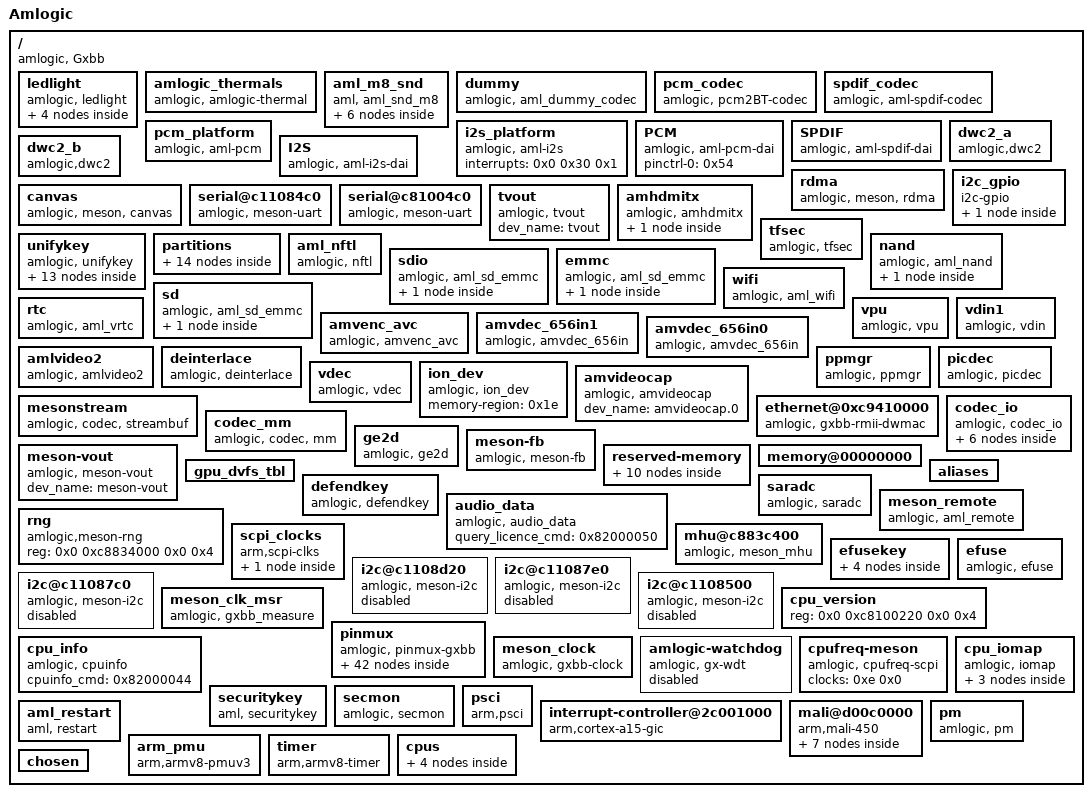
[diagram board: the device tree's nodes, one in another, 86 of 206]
/dts-v1/;

/ {
	#size-cells = <0x2>;
	#address-cells = <0x2>;
	interrupt-parent = <0x1>;
	amlogic-dt-id = "gxbb_p201_1g";
	compatible = "amlogic, Gxbb";
	model = "Amlogic";

	ledlight {
		ir_gpio_0 = <0x6a>;
		net_gpio_1 = <0x69>;
		net_gpio_0 = <0x68>;
		power_gpio_0 = <0x67>;
		status = "okay";
		dev_name = "ledlight";
		compatible = "amlogic, ledlight";

		gpio_b {
			phandle = <0x6a>;
			linux,phandle = <0x6a>;
			led_type = [42 00];
			led_active = <0x0>;
			led_gpio = <0x1a 0x58 0x0>;
			led_name = "ir_led";
		};

		gpio_g {
			phandle = <0x69>;
			linux,phandle = <0x69>;
			led_type = [47 00];
			led_active = <0x0>;
			led_gpio = <0x1a 0x52 0x0>;
			led_name = "net_led";
		};

		gpio_r {
			phandle = <0x68>;
			linux,phandle = <0x68>;
			led_type = [52 00];
			led_active = <0x0>;
			led_gpio = <0x1a 0x55 0x0>;
			led_name = "net_led";
		};

		gpio_rg {
			phandle = <0x67>;
			linux,phandle = <0x67>;
			led_type = "R&G";
			led_active = <0x1>;
			led_gpio = <0x6b 0xd 0x0>;
			led_name = "power_led";
		};
	};

	amlogic_thermals {
		keep_mode_min_range = <0x1f4 0x190 0x1 0x2>;
		keep_mode_max_range = <0x1ec300 0x29a 0x4 0x3>;
		keep_mode_threshold = <0x55>;
		keep_mode;
		idle_interval = <0x3e8>;
		cpu_cali_a = <0x0>;
		trip_point = <0x46 0x177001 0x177001 0x1ff 0x1ff 0x3 0x2 0x50 0x13c681 0x13c681 0x1b3 0x1b3 0x2 0x1 0x5a 0xfbf41 0xfbf41 0x148 0x148 0x2 0x1 0x104 0xffffffff 0xffffffff 0xffffffff 0xffffffff 0xffffffff 0xffffffff>;
		dev_name = "aml_thermal";
		#thermal-cells = <0x7>;
		compatible = "amlogic, amlogic-thermal";
	};

	aml_m8_snd {
		plat_list = <0x5f 0x5f 0x60>;
		codec_list = <0x5c 0x5d 0x5e>;
		cpu_list = <0x59 0x5a 0x5b>;
		pinctrl-1 = <0x58>;
		pinctrl-0 = <0x57>;
		pinctrl-names = "aml_snd_m8", "aml_snd_suspend";
		hp_paraments = <0x320 0x12c 0x0 0x5 0x1>;
		hp_disable;
		mute_gpio-gpios = <0x1a 0x13 0x0>;
		aml,audio-routing = "Ext Spk", "LOUTL", "Ext Spk", "LOUTR";
		aml_sound_card,name = "AML-M8AUDIO";
		aml-sound-card,format = "i2s";
		status = "okay";
		compatible = "aml, aml_snd_m8";

		codec2 {
			phandle = <0x5e>;
			linux,phandle = <0x5e>;
			sound-dai = <0x66>;
		};

		codec1 {
			phandle = <0x5d>;
			linux,phandle = <0x5d>;
			sound-dai = <0x65>;
		};

		codec0 {
			phandle = <0x5c>;
			linux,phandle = <0x5c>;
			sound-dai = <0x64>;
		};

		cpudai2 {
			phandle = <0x5b>;
			linux,phandle = <0x5b>;
			sound-dai = <0x63>;
		};

		cpudai1 {
			phandle = <0x5a>;
			linux,phandle = <0x5a>;
			sound-dai = <0x62>;
		};

		cpudai0 {
			phandle = <0x59>;
			linux,phandle = <0x59>;
			sound-dai = <0x61>;
		};
	};

	dummy {
		phandle = <0x64>;
		linux,phandle = <0x64>;
		status = "okay";
		compatible = "amlogic, aml_dummy_codec";
		#sound-dai-cells = <0x0>;
	};

	pcm_codec {
		phandle = <0x66>;
		linux,phandle = <0x66>;
		compatible = "amlogic, pcm2BT-codec";
		#sound-dai-cells = <0x0>;
	};

	spdif_codec {
		phandle = <0x65>;
		linux,phandle = <0x65>;
		pinctrl-1 = <0x56>;
		pinctrl-0 = <0x55>;
		pinctrl-names = "aml_audio_spdif", "aml_audio_spdif_suspend";
		compatible = "amlogic, aml-spdif-codec";
		#sound-dai-cells = <0x0>;
	};

	pcm_platform {
		phandle = <0x60>;
		linux,phandle = <0x60>;
		compatible = "amlogic, aml-pcm";
	};

	i2s_platform {
		phandle = <0x5f>;
		linux,phandle = <0x5f>;
		interrupts = <0x0 0x30 0x1>;
		compatible = "amlogic, aml-i2s";
	};

	PCM {
		phandle = <0x63>;
		linux,phandle = <0x63>;
		pinctrl-0 = <0x54>;
		pinctrl-names = "aml_audio_btpcm";
		compatible = "amlogic, aml-pcm-dai";
		#sound-dai-cells = <0x0>;
	};

	SPDIF {
		phandle = <0x62>;
		linux,phandle = <0x62>;
		clock-names = "mpll1", "i958", "mclk", "spdif", "clk_81";
		clocks = <0xb 0x20 0xb 0x24 0xb 0x22 0xb 0x25 0xb 0xa>;
		reset-names = "iec958", "iec958_amclk";
		resets = <0xb 0x27 0xb 0x90>;
		compatible = "amlogic, aml-spdif-dai";
		#sound-dai-cells = <0x0>;
	};

	I2S {
		phandle = <0x61>;
		linux,phandle = <0x61>;
		compatible = "amlogic, aml-i2s-dai";
		clock-names = "mpll0", "mclk";
		clocks = <0xb 0x1f 0xb 0x22>;
		reset-names = "top_glue", "aud_buf", "i2s_out", "amclk_measure", "aififo2", "aud_mixer", "mixer_reg", "adc", "top_level", "aoclk", "aud_in";
		resets = <0xb 0x26 0xb 0x12 0xb 0x28 0xb 0x29 0xb 0x2a 0xb 0x2b 0xb 0x2c 0xb 0x2d 0xb 0x2f 0xb 0x8e 0xb 0x22>;
		#sound-dai-cells = <0x0>;
	};

	dwc2_a {
		reset-names = "usb_general", "usb0", "usb0_to_ddr";
		resets = <0xb 0x3a 0xb 0x49 0xb 0x35>;
		cpu-type = "gxbaby";
		usb-fifo = <0x400>;
		phy-reg-size = <0x20>;
		phy-reg = <0xc0000000>;
		gpio-work-mask = <0x1>;
		gpios = <0x1a 0x45 0x0>;
		gpio-vbus-power = "GPIODV_24";
		port-id-mode = <0x1>;
		port-dma = <0x0>;
		port-config = <0x0>;
		port-speed = <0x0>;
		port-type = <0x1>;
		port-id = <0x0>;
		clock-src = "usb0";
		pl-periph-id = <0x0>;
		status = "okay";
		interrupts = <0x0 0x1e 0x4>;
		reg = <0x0 0xc9000000 0x0 0x40000>;
		compatible = "amlogic,dwc2";
	};

	dwc2_b {
		reset-names = "usb_general", "usb1", "usb1_to_ddr";
		resets = <0xb 0x3a 0xb 0x48 0xb 0x36>;
		cpu-type = "gxbaby";
		pmu-apply-power = <0x1>;
		host-only-core = <0x1>;
		usb-fifo = <0x400>;
		phy-reg-size = <0x20>;
		phy-reg = <0xc0000020>;
		port-id-mode = <0x1>;
		port-dma = <0x0>;
		port-config = <0x0>;
		port-speed = <0x0>;
		port-type = <0x1>;
		port-id = <0x1>;
		clock-src = "usb1";
		pl-periph-id = <0x1>;
		status = "okay";
		interrupts = <0x0 0x1f 0x4>;
		reg = <0x0 0xc9100000 0x0 0x40000>;
		compatible = "amlogic,dwc2";
	};

	rdma {
		interrupt-names = "rdma";
		interrupts = <0x0 0x59 0x1>;
		status = "ok";
		dev_name = "amlogic-rdma";
		compatible = "amlogic, meson, rdma";
	};

	canvas {
		reg = <0x0 0xc8838000 0x0 0x400>;
		status = "ok";
		dev_name = "amlogic-canvas";
		compatible = "amlogic, meson, canvas";
	};

	serial@c11084c0 {
		resets = <0xb 0xd>;
		pinctrl-0 = <0x53>;
		pinctrl-names = "default";
		fifosize = <0x80>;
		clock-names = "clk_uart";
		clocks = <0xb 0x2>;
		status = "okay";
		interrupts = <0x0 0x1a 0x1>;
		reg = <0x0 0xc11084c0 0x0 0x14>;
		compatible = "amlogic, meson-uart";
	};

	serial@c81004c0 {
		pinctrl-names = "default";
		fifosize = <0x40>;
		clock-names = "clk_uart";
		clocks = <0xb 0x2>;
		status = "okay";
		interrupts = <0x0 0xc1 0x1>;
		reg = <0x0 0xc81004c0 0x0 0x14>;
		compatible = "amlogic, meson-uart";
	};

	i2c_gpio {
		i2c-gpio,timeout-ms = <0xa>;
		#size-cells = <0x2>;
		#address-cells = <0x2>;
		gpios = <0x1a 0x11 0x0 0x1a 0x12 0x0>;
		i2c-gpio,delay-us = <0xa>;
		dev_name = "i2c-gpio";
		compatible = "i2c-gpio";

		i2c_gpio_edid {
			reg = <0x50 0x0 0x0 0x0>;
			compatible = "i2c-gpio-edid";
		};
	};

	tvout {
		status = "okay";
		dev_name = "tvout";
		compatible = "amlogic, tvout";
	};

	amhdmitx {
		ranges;
		#size-cells = <0x2>;
		#address-cells = <0x2>;
		gpio_i2c_en = <0x1>;
		clock-names = "hdmitx_clk_sys", "hdmitx_clk_encp", "hdmitx_clk_enci", "hdmitx_clk_pixel", "hdmitx_clk_phy", "hdmitx_clk_vid";
		clocks = <0xb 0xb 0xb 0xc 0xb 0xd 0xb 0xe 0xb 0xf 0xb 0x16>;
		interrupt-names = "hdmitx_hpd";
		interrupts = <0x0 0x39 0x1>;
		vend-data = <0x51>;
		pinctrl-1 = <0x50>;
		pinctrl-0 = <0x4f>;
		pinctrl-names = "hdmitx_hpd", "hdmitx_ddc";
		status = "okay";
		dev_name = "amhdmitx";
		compatible = "amlogic, amhdmitx";

		vend_data {
			phandle = <0x51>;
			linux,phandle = <0x51>;
			reg = <0x0 0xc810023c 0x0 0x4>;
			pinctrl-0 = <0x52>;
			pinctrl-names = "hdmitx_aocec";
			interrupt-names = "hdmitx_cec";
			interrupts = <0x0 0xc7 0x1>;
			cec_osd_string = "MBox";
			product_desc = "GXBB Mbox";
			vendor_id = <0x0>;
			vendor_name = "Amlogic";
			status = "okay";
			compatible = "amlogic, amlogic-cec";
		};
	};

	tfsec {
		tap_query_in = <0xb000ff0a>;
		tap_get_ci = <0xb000ff09>;
		tap_get_mac = <0xb000ff08>;
		tap_burn_mac = <0xb000ff07>;
		tap_burn_ci = <0xb000ff06>;
		tap_burn_sn = <0xb000ff05>;
		tap_burn_in = <0xb000ff04>;
		tap_decrypt_terminal_challenge = <0xb000ff03>;
		tap_decrypt_cloud_challenge = <0xb000ff02>;
		tap_get_sn = <0xb000ff01>;
		compatible = "amlogic, tfsec";
	};

	unifykey {
		unifykey-index-12 = <0x4e>;
		unifykey-index-11 = <0x4d>;
		unifykey-index-10 = <0x4c>;
		unifykey-index-9 = <0x4b>;
		unifykey-index-8 = <0x4a>;
		unifykey-index-7 = <0x49>;
		unifykey-index-6 = <0x48>;
		unifykey-index-5 = <0x47>;
		unifykey-index-4 = <0x46>;
		unifykey-index-3 = <0x45>;
		unifykey-index-2 = <0x44>;
		unifykey-index-1 = <0x43>;
		unifykey-index-0 = <0x42>;
		unifykey-num = <0xd>;
		status = "ok";
		compatible = "amlogic, unifykey";

		key_12 {
			phandle = <0x4e>;
			linux,phandle = <0x4e>;
			key-permit = "read", "write", "del";
			key-device = "normal";
			key-name = "stbid";
		};

		key_11 {
			phandle = <0x4d>;
			linux,phandle = <0x4d>;
			key-permit = "read", "write", "del";
			key-type = "raw";
			key-device = "secure";
			key-name = "telecomkeybox";
		};

		key_10 {
			phandle = <0x4c>;
			linux,phandle = <0x4c>;
			key-permit = "read", "write", "del";
			key-device = "secure";
			key-name = "hdcp22_fw_private";
		};

		key_9 {
			phandle = <0x4b>;
			linux,phandle = <0x4b>;
			key-permit = "read", "write", "del";
			key-device = "normal";
			key-name = "deviceid";
		};

		key_8 {
			phandle = <0x4a>;
			linux,phandle = <0x4a>;
			key-permit = "read", "write", "del";
			key-device = "secure";
			key-name = "widevinekeybox";
		};

		key_7 {
			phandle = <0x49>;
			linux,phandle = <0x49>;
			key-permit = "read", "write", "del";
			key-device = "normal";
			key-name = "hdcp2_rx";
		};

		key_6 {
			phandle = <0x48>;
			linux,phandle = <0x48>;
			key-permit = "read", "write", "del";
			key-device = "normal";
			key-name = "hdcp2_tx";
		};

		key_5 {
			phandle = <0x47>;
			linux,phandle = <0x47>;
			key-type = "mac";
			key-permit = "read", "write", "del";
			key-device = "normal";
			key-name = "mac_wifi";
		};

		key_4 {
			phandle = <0x46>;
			linux,phandle = <0x46>;
			key-type = "mac";
			key-permit = "read", "write", "del";
			key-device = "normal";
			key-name = "mac_bt";
		};

		key_3 {
			phandle = <0x45>;
			linux,phandle = <0x45>;
			key-permit = "write";
			key-device = "efuse";
			key-name = "secure_boot_set";
		};

		key_2 {
			phandle = <0x44>;
			linux,phandle = <0x44>;
			key-permit = "read", "write", "del";
			key-type = "sha1";
			key-device = "secure";
			key-name = "hdcp";
		};

		key_1 {
			phandle = <0x43>;
			linux,phandle = <0x43>;
			key-permit = "read", "write", "del";
			key-device = "normal";
			key-name = "mac";
		};

		key_0 {
			phandle = <0x42>;
			linux,phandle = <0x42>;
			key-permit = "read", "write", "del";
			key-device = "normal";
			key-name = "usid";
		};
	};

	partitions {
		part-13 = <0x41>;
		part-12 = <0x40>;
		part-11 = <0x3f>;
		part-10 = <0x3e>;
		part-9 = <0x3d>;
		part-8 = <0x3c>;
		part-7 = <0x3b>;
		part-6 = <0x3a>;
		part-5 = <0x39>;
		part-4 = <0x38>;
		part-3 = <0x37>;
		part-2 = <0x36>;
		part-1 = <0x35>;
		part-0 = <0x34>;
		parts = <0xe>;

		data {
			phandle = <0x41>;
			linux,phandle = <0x41>;
			mask = <0x4>;
			size = <0xffffffff 0xffffffff>;
			pname = "data";
		};

		params {
			phandle = <0x40>;
			linux,phandle = <0x40>;
			mask = <0x2>;
			size = <0x0 0x4000000>;
			pname = "params";
		};

		info {
			phandle = <0x3f>;
			linux,phandle = <0x3f>;
			mask = <0x4>;
			size = <0x0 0x4000000>;
			pname = "info";
		};

		ghost {
			phandle = <0x3e>;
			linux,phandle = <0x3e>;
			mask = <0x4>;
			size = <0x0 0x20000000>;
			pname = "ghost";
		};

		cache {
			phandle = <0x3d>;
			linux,phandle = <0x3d>;
			mask = <0x2>;
			size = <0x0 0x20000000>;
			pname = "cache";
		};

		system {
			phandle = <0x3c>;
			linux,phandle = <0x3c>;
			mask = <0x1>;
			size = <0x0 0x28000000>;
			pname = "system";
		};

		boot {
			phandle = <0x3b>;
			linux,phandle = <0x3b>;
			mask = <0x1>;
			size = <0x0 0x2000000>;
			pname = "boot";
		};

		instaboot {
			phandle = <0x3a>;
			linux,phandle = <0x3a>;
			mask = <0x1>;
			size = <0x0 0x20000000>;
			pname = "instaboot";
		};

		misc {
			phandle = <0x39>;
			linux,phandle = <0x39>;
			mask = <0x1>;
			size = <0x0 0x2000000>;
			pname = "misc";
		};

		crypt {
			phandle = <0x38>;
			linux,phandle = <0x38>;
			mask = <0x1>;
			size = <0x0 0x2000000>;
			pname = "crypt";
		};

		tee {
			phandle = <0x37>;
			linux,phandle = <0x37>;
			mask = <0x1>;
			size = <0x0 0x800000>;
			pname = "tee";
		};

		rsv {
			phandle = <0x36>;
			linux,phandle = <0x36>;
			mask = <0x1>;
			size = <0x0 0x800000>;
			pname = "rsv";
		};

		recovery {
			phandle = <0x35>;
			linux,phandle = <0x35>;
			mask = <0x1>;
			size = <0x0 0x2000000>;
			pname = "recovery";
		};

		logo {
			phandle = <0x34>;
			linux,phandle = <0x34>;
			mask = <0x1>;
			size = <0x0 0x2000000>;
			pname = "logo";
		};
	};

	aml_nftl {
		compatible = "amlogic, nftl";
	};

	nand {
		plat-part-0 = <0x33>;
		plat-num = <0x1>;
		plat-names = "nandnormal";
		device_id = <0x0>;
		pinctrl-2 = <0x32>;
		pinctrl-1 = <0x2f 0x30 0x31>;
		pinctrl-0 = <0x2f 0x30 0x31>;
		pinctrl-names = "nand_rb_mod", "nand_norb_mod", "nand_cs_pins_only";
		interrupts = <0x0 0x22 0x1>;
		reg = <0x0 0xd0074800 0x0 0x200>;
		status = "ok";
		dev_name = "nand";
		compatible = "amlogic, aml_nand";

		normal {
			phandle = <0x33>;
			linux,phandle = <0x33>;
			busy_pad = "rb0";
			enable_pad = "ce0", "ce1", "ce2", "ce3";
		};
	};

	sdio {
		pinctrl-1 = <0x2e>;
		pinctrl-0 = <0x2d>;
		pinctrl-names = "sdio_clk_cmd_pins", "sdio_all_pins";
		interrupts = <0x0 0xd8 0x4>;
		reg = <0x0 0xd0070000 0x0 0x2000>;
		status = "okay";
		dev_name = "aml_newsd.0";
		compatible = "amlogic, aml_sd_emmc";

		sdio {
			card_type = <0x3>;
			max_req_size = <0x20000>;
			f_max = <0xbebc200>;
			f_min = <0x61a80>;
			caps = "MMC_CAP_4_BIT_DATA", "MMC_CAP_MMC_HIGHSPEED", "MMC_CAP_SD_HIGHSPEED", "MMC_CAP_NONREMOVABLE", "MMC_CAP_UHS_SDR12", "MMC_CAP_UHS_SDR25", "MMC_CAP_UHS_SDR50", "MMC_CAP_UHS_SDR104", "MMC_PM_KEEP_POWER", "MMC_CAP_SDIO_IRQ";
			ocr_avail = <0x200080>;
			pinname = "sdio";
			status = "okay";
		};
	};

	emmc {
		pinctrl-1 = <0x2c>;
		pinctrl-0 = <0x2b>;
		pinctrl-names = "emmc_clk_cmd_pins", "emmc_all_pins";
		interrupts = <0x0 0xda 0x1>;
		reg = <0x0 0xd0074000 0x0 0x2000>;
		status = "okay";
		dev_name = "aml_newsd.0";
		compatible = "amlogic, aml_sd_emmc";

		emmc {
			card_type = <0x1>;
			hw_reset = <0x1a 0x1d 0x0>;
			gpio_dat3 = <0x1a 0x17 0x0>;
			max_req_size = <0x20000>;
			f_max = <0xbebc200>;
			f_min = <0x493e0>;
			caps2 = "MMC_CAP2_HS200";
			caps = "MMC_CAP_8_BIT_DATA", "MMC_CAP_MMC_HIGHSPEED", "MMC_CAP_SD_HIGHSPEED", "MMC_CAP_NONREMOVABLE", "MMC_CAP_1_8V_DDR", "MMC_CAP_HW_RESET", "MMC_CAP_ERASE", "MMC_CAP_CMD23";
			ocr_avail = <0x200080>;
			pinname = "emmc";
			status = "okay";
		};
	};

	sd {
		pinctrl-8 = <0x2a>;
		pinctrl-7 = <0x29>;
		pinctrl-6 = <0x28>;
		pinctrl-5 = <0x27>;
		pinctrl-4 = <0x26>;
		pinctrl-3 = <0x25>;
		pinctrl-2 = <0x24>;
		pinctrl-1 = <0x23>;
		pinctrl-0 = <0x22>;
		pinctrl-names = "sd_clk_cmd_pins", "sd_all_pins", "sd_1bit_pins", "sd_clk_cmd_uart_pins", "sd_1bit_uart_pins", "sd_to_ao_uart_pins", "ao_to_sd_uart_pins", "ao_to_sd_jtag_pins", "sd_to_ao_jtag_pins";
		interrupts = <0x0 0xd9 0x1 0x0 0x43 0x1 0x0 0x45 0x1>;
		reg = <0x0 0xd0072000 0x0 0x2000>;
		status = "okay";
		dev_name = "aml_newsd.0";
		compatible = "amlogic, aml_sd_emmc";

		sd {
			card_type = <0x5>;
			irq_out = <0x5>;
			irq_in = <0x3>;
			gpio_cd = <0x1a 0x2c 0x0>;
			jtag_pin = <0x1a 0x26 0x0>;
			gpio_dat3 = <0x1a 0x2a 0x0>;
			max_req_size = <0x20000>;
			tx_phase = <0x0>;
			f_max = <0x5f5e100>;
			f_min = <0x61a80>;
			caps = "MMC_CAP_4_BIT_DATA", "MMC_CAP_MMC_HIGHSPEED", "MMC_CAP_SD_HIGHSPEED";
			ocr_avail = <0x200080>;
			pinname = "sd";
			port = <0x1>;
			status = "okay";
		};
	};

	wifi {
		pinctrl-0 = <0x21>;
		pinctrl-names = "wifi_32k_pins";
		dhd_static_buf;
		power_on_pin = <0x1a 0x62 0x0>;
		irq_trigger_type = "GPIO_IRQ_HIGH";
		interrupts = <0x0 0x44 0x4>;
		interrupt_pin = <0x1a 0x63 0x0>;
		status = "okay";
		dev_name = "aml_wifi";
		compatible = "amlogic, aml_wifi";
	};

	rtc {
		status = "okay";
		init_date = "2015/01/01";
		timer_e_addr = <0xc1109988>;
		alarm_reg_addr = <0xc81000a8>;
		compatible = "amlogic, aml_vrtc";
	};

	vpu {
		clk_level = <0x7>;
		status = "ok";
		dev_name = "vpu";
		compatible = "amlogic, vpu";
	};

	amvenc_avc {
		interrupt-names = "mailbox_2";
		interrupts = <0x0 0x2d 0x1>;
		status = "okay";
		dev_name = "amvenc_avc";
		compatible = "amlogic, amvenc_avc";
	};

	amvdec_656in1 {
		bt656_id = <0x1>;
		clock-names = "fclk_div2", "cts_bt656_clk1";
		clocks = <0xb 0x7 0xb 0x27>;
		reg = <0x0 0xd0050000 0x0 0x7c>;
		status = "ok";
		dev_name = "amvdec_656in1";
		compatible = "amlogic, amvdec_656in";
	};

	amvdec_656in0 {
		bt656_id = <0x0>;
		clock-names = "fclk_div2", "cts_bt656_clk0";
		clocks = <0xb 0x7 0xb 0x26>;
		reg = <0x0 0xd0048000 0x0 0x7c>;
		status = "ok";
		dev_name = "amvdec_656in0";
		compatible = "amlogic, amvdec_656in";
	};

	vdin1 {
		vdin_id = <0x1>;
		clock-names = "xtal", "cts_vid_lock_clk";
		clocks = <0xb 0x2 0xb 0x28>;
		rdma-irq = <0x4>;
		interrupts = <0x0 0x55 0x1>;
		reserve-iomap = "true";
		status = "ok";
		dev_name = "vdin1";
		memory-region = <0x6>;
		compatible = "amlogic, vdin";
	};

	amlvideo2 {
		status = "okay";
		dev_name = "amlvideo2";
		memory-region = <0x20>;
		compatible = "amlogic, amlvideo2";
	};

	deinterlace {
		hw-version = <0x2>;
		buffer-size = <0x2fd000>;
		interrupt-names = "de_irq", "timerc";
		interrupts = <0x0 0x2e 0x1 0x0 0x6 0x1>;
		memory-region = <0x1f>;
		status = "okay";
		compatible = "amlogic, deinterlace";
	};

	ppmgr {
		status = "okay";
		dev_name = "ppmgr";
		memory-region = <0x1e>;
		compatible = "amlogic, ppmgr";
	};

	picdec {
		status = "okay";
		dev_name = "picdec";
		memory-region = <0x4>;
		compatible = "amlogic, picdec";
	};

	vdec {
		interrupt-names = "vsync", "demux", "parser", "mailbox_0", "mailbox_1", "mailbox_2";
		interrupts = <0x0 0x3 0x1 0x0 0x17 0x1 0x0 0x20 0x1 0x0 0x2b 0x1 0x0 0x2c 0x1 0x0 0x2d 0x1>;
		status = "okay";
		dev_name = "vdec.0";
		compatible = "amlogic, vdec";
	};

	ion_dev {
		memory-region = <0x1e>;
		compatible = "amlogic, ion_dev";
	};

	amvideocap {
		status = "okay";
		dev_name = "amvideocap.0";
		compatible = "amlogic, amvideocap";
	};

	mesonstream {
		reset-names = "parser_top", "vpu_intr", "demux", "vdec";
		resets = <0xb 0x39 0xb 0x59 0xb 0x24 0xb 0x1>;
		status = "okay";
		dev_name = "mesonstream";
		compatible = "amlogic, codec, streambuf";
	};

	ethernet@0xc9410000 {
		clock-names = "ethclk81";
		clocks = <0xb 0xa>;
		interrupt-names = "macirq";
		reset-names = "ethpower";
		resets = <0xb 0x23>;
		mc_val = <0x1800>;
		rst_pin-gpios = <0x1a 0xe 0x0>;
		pinctrl-0 = <0x1d>;
		pinctrl-names = "eth_pins";
		phy-mode = "rmii";
		interrupts = <0x0 0x8 0x1>;
		reg = <0x0 0xc9410000 0x0 0x10000 0x0 0xc8834540 0x0 0x8>;
		compatible = "amlogic, gxbb-rmii-dwmac";
	};

	codec_mm {
		status = "okay";
		dev_name = "codec_mm";
		memory-region = <0x3 0x1c>;
		compatible = "amlogic, codec, mm";
	};

	codec_io {
		ranges;
		#size-cells = <0x2>;
		#address-cells = <0x2>;
		compatible = "amlogic, codec_io";

		io_dmc_base {
			reg = <0x0 0xc8838000 0x0 0x400>;
		};

		io_vcbus_base {
			reg = <0x0 0xd0100000 0x0 0x40000>;
		};

		io_aobus_base {
			reg = <0x0 0xc8100000 0x0 0x100000>;
		};

		io_hiubus_base {
			reg = <0x0 0xc883c000 0x0 0x2000>;
		};

		io_dos_base {
			reg = <0x0 0xc8820000 0x0 0x10000>;
		};

		io_cbus_base {
			reg = <0x0 0xc1100000 0x0 0x100000>;
		};
	};

	ge2d {
		reset-names = "ge2d";
		resets = <0xb 0x34>;
		clock-names = "clk_vapb_0", "clk_ge2d";
		clocks = <0xb 0x17 0xb 0x19>;
		interrupt-names = "ge2d";
		interrupts = <0x0 0x96 0x1>;
		status = "okay";
		dev_name = "ge2d";
		compatible = "amlogic, ge2d";
	};

	meson-fb {
		display_size_default = <0x780 0x438 0x780 0xca8 0x20>;
		scale_mode = <0x1>;
		display_mode_default = "1080p60hz";
		mem_size = <0x1800000 0x100000>;
		interrupt-names = "viu-vsync", "rdma";
		interrupts = <0x0 0x3 0x1 0x0 0x59 0x1>;
		status = "okay";
		dev_name = "meson-fb";
		memory-region = <0x1b>;
		compatible = "amlogic, meson-fb";
	};

	meson-vout {
		status = "okay";
		dev_name = "meson-vout";
		compatible = "amlogic, meson-vout";
	};

	reserved-memory {
		ranges;
		#size-cells = <0x2>;
		#address-cells = <0x2>;

		linux,codec_mm_reserved {
			phandle = <0x1c>;
			linux,phandle = <0x1c>;
			alignment = <0x0 0x100000>;
			size = <0x0 0x4100000>;
			compatible = "amlogic, codec-mm-reserved";
		};

		linux,picdec {
			linux,contiguous-region;
			alignment = <0x0 0x0>;
			size = <0x0 0x0>;
			reusable;
			linux,phandle = <0x4>;
			compatible = "shared-dma-pool";
		};

		linux,codec_mm_cma {
			linux,contiguous-region;
			alignment = <0x0 0x400000>;
			size = <0x0 0xd000000>;
			reusable;
			linux,phandle = <0x3>;
			compatible = "shared-dma-pool";
		};

		linux,amlvideo2 {
			phandle = <0x20>;
			linux,phandle = <0x20>;
			size = <0x0 0x1800000>;
			compatible = "amlogic, amlvideo2_memory";
		};

		linux,vdin1_cma {
			alignment = <0x0 0x400000>;
			size = <0x0 0x1400000>;
			reusable;
			linux,phandle = <0x6>;
			compatible = "shared-dma-pool";
		};

		linux,ion-dev {
			phandle = <0x1e>;
			linux,phandle = <0x1e>;
			multi-use;
			size = <0x0 0x2000000>;
			compatible = "amlogic, idev-mem";
		};

		linux,di {
			phandle = <0x1f>;
			linux,phandle = <0x1f>;
			multi-use;
			size = <0x0 0x1e00000>;
			compatible = "amlogic, di-mem";
		};

		linux,meson-fb {
			phandle = <0x1b>;
			linux,phandle = <0x1b>;
			no-map;
			size = <0x0 0x1900000>;
			compatible = "amlogic, fb-memory";
		};

		aml_pstore {
			no-map;
			reg = <0x0 0x20000000 0x0 0x100000>;
			compatible = "amlogic, pstore";
		};

		linux,secmon {
			phandle = <0xd>;
			linux,phandle = <0xd>;
			no-map;
			reg = <0x0 0x10000000 0x0 0x200000>;
			compatible = "amlogic, aml_secmon_memory";
		};
	};

	memory@00000000 {
		linux,usable-memory = <0x0 0x1000000 0x0 0x3f000000>;
		device_type = "memory";
		reg = <0x0 0x0 0x0 0x38000000>;
	};

	gpu_dvfs_tbl {
		phandle = <0xc>;
		linux,phandle = <0xc>;
		tbl = <0x5 0x7 0x8 0x9 0xa>;
		sc_mpp = <0x3>;
	};

	aliases {
		serial1 = "/serial@c11084c0";
		serial0 = "/serial@c81004c0";
	};

	defendkey {
		status = "okay";
		mem_size = <0x0 0x100000>;
		reg = <0x0 0xc8834500 0x0 0x4>;
		compatible = "amlogic, defendkey";
	};

	saradc {
		reg = <0x0 0xc1108680 0x0 0x30 0x0 0xc883c3d8 0x0 0x8>;
		resets = <0xb 0x56>;
		clock-names = "saradc_clk";
		clocks = <0xb 0x2>;
		interrupt-names = "saradc_int";
		interrupts = <0x0 0x9 0x1>;
		status = "okay";
		compatible = "amlogic, saradc";
	};

	audio_data {
		status = "okay";
		query_licence_cmd = <0x82000050>;
		compatible = "amlogic, audio_data";
	};

	rng {
		reg = <0x0 0xc8834000 0x0 0x4>;
		compatible = "amlogic,meson-rng";
	};

	meson_remote {
		led_pin = <0x1a 0x58 0x0>;
		led_status_on = <0x0>;
		pinctrl-0 = <0x19>;
		pinctrl-names = "default";
		interrupts = <0x0 0xc4 0x1>;
		remote_ao_offset = <0x580>;
		status = "ok";
		dev_name = "meson-remote";
		compatible = "amlogic, aml_remote";
	};

	scpi_clocks {
		compatible = "arm,scpi-clks";

		scpi_clocks@0 {
			phandle = <0xe>;
			linux,phandle = <0xe>;
			clock-output-names = "vcpu";
			clock-indices = <0x0>;
			#clock-cells = <0x1>;
			compatible = "arm,scpi-clk-indexed";
		};
	};

	mhu@c883c400 {
		phandle = <0x18>;
		linux,phandle = <0x18>;
		mboxes = <0x18 0x0 0x18 0x1>;
		mbox-names = "cpu_to_scp_low", "cpu_to_scp_high";
		#mbox-cells = <0x1>;
		interrupts = <0x0 0xd1 0x8 0x0 0xd2 0x8>;
		reg = <0x0 0xc883c400 0x0 0x4c 0x0 0xc8013000 0x0 0x800>;
		compatible = "amlogic, meson_mhu";
	};

	efusekey {
		phandle = <0x13>;
		linux,phandle = <0x13>;
		key3#1 = <0x17>;
		key2#1 = <0x16>;
		key1#1 = <0x15>;
		key0#1 = <0x14>;
		keynum = <0x4>;

		key3 {
			phandle = <0x17>;
			linux,phandle = <0x17>;
			size = <0x14>;
			offset = <0x12>;
			keyname = "usid";
		};

		key2 {
			phandle = <0x16>;
			linux,phandle = <0x16>;
			size = <0x6>;
			offset = <0xc>;
			keyname = "mac_wifi";
		};

		key1 {
			phandle = <0x15>;
			linux,phandle = <0x15>;
			size = <0x6>;
			offset = <0x6>;
			keyname = "mac_bt";
		};

		key0 {
			phandle = <0x14>;
			linux,phandle = <0x14>;
			size = <0x6>;
			offset = <0x0>;
			keyname = "mac";
		};
	};

	efuse {
		status = "okay";
		reset-names = "efuse_clk";
		resets = <0xb 0x3e>;
		key = <0x13>;
		get_max_cmd = <0x82000033>;
		write_cmd = <0x82000031>;
		read_cmd = <0x82000030>;
		compatible = "amlogic, efuse";
	};

	i2c@c1108d20 {
		resets = <0xb 0x9>;
		clock-names = "clk_i2c";
		clocks = <0xb 0xa>;
		master_i2c_speed = <0x493e0>;
		use_pio = <0x0>;
		#size-cells = <0x0>;
		#address-cells = <0x1>;
		pinctrl-0 = <0x12>;
		pinctrl-names = "default";
		device_id = <0x4>;
		reg = <0x0 0xc1108d20 0x0 0x20>;
		status = "disabled";
		dev_name = "i2c-D";
		compatible = "amlogic, meson-i2c";
	};

	i2c@c11087e0 {
		resets = <0xb 0x9>;
		clock-names = "clk_i2c";
		clocks = <0xb 0xa>;
		master_i2c_speed = <0x493e0>;
		use_pio = <0x0>;
		#size-cells = <0x0>;
		#address-cells = <0x1>;
		pinctrl-0 = <0x11>;
		pinctrl-names = "default";
		device_id = <0x3>;
		reg = <0x0 0xc11087e0 0x0 0x20>;
		status = "disabled";
		dev_name = "i2c-C";
		compatible = "amlogic, meson-i2c";
	};

	i2c@c11087c0 {
		resets = <0xb 0x9>;
		clock-names = "clk_i2c";
		clocks = <0xb 0xa>;
		master_i2c_speed = <0x493e0>;
		use_pio = <0x0>;
		#size-cells = <0x0>;
		#address-cells = <0x1>;
		pinctrl-0 = <0x10>;
		pinctrl-names = "default";
		device_id = <0x2>;
		reg = <0x0 0xc11087c0 0x0 0x20>;
		status = "disabled";
		dev_name = "i2c-B";
		compatible = "amlogic, meson-i2c";
	};

	i2c@c1108500 {
		resets = <0xb 0x9>;
		clock-names = "clk_i2c";
		clocks = <0xb 0xa>;
		master_i2c_speed = <0x493e0>;
		use_pio = <0x0>;
		#size-cells = <0x0>;
		#address-cells = <0x1>;
		pinctrl-0 = <0xf>;
		pinctrl-names = "default";
		device_id = <0x1>;
		reg = <0x0 0xc1108500 0x0 0x20>;
		status = "disabled";
		dev_name = "i2c-A";
		compatible = "amlogic, meson-i2c";
	};

	meson_clk_msr {
		reg = <0x0 0xc110875c 0x0 0x4 0x0 0xc1108764 0x0 0x4>;
		compatible = "amlogic, gxbb_measure";
	};

	cpu_version {
		reg = <0x0 0xc8100220 0x0 0x4>;
	};

	pinmux {
		ranges;
		reg = <0x0 0xc1109880 0x0 0x10>;
		#size-cells = <0x2>;
		#address-cells = <0x2>;
		#pinmux-cells = <0x2>;
		dev_name = "pinmux";
		compatible = "amlogic, pinmux-gxbb";

		audio_btpcm_pins {
			phandle = <0x54>;
			linux,phandle = <0x54>;
			amlogic,pins = "GPIOX_8", "GPIOX_9", "GPIOX_10", "GPIOX_11";
			amlogic,clrmask = <0x3 0x803280 0x4 0xc0>;
			amlogic,setmask = <0x3 0x78000000>;
		};

		audio_spdif_sus_pin {
			phandle = <0x56>;
			linux,phandle = <0x56>;
			amlogic,pullup = <0x0>;
			amlogic,pullupen = <0x1>;
			amlogic,pins = "GPIOY_12";
			amlogic,clrmask = <0x1 0x10200>;
		};

		audio_pin1 {
			phandle = <0x55>;
			linux,phandle = <0x55>;
			amlogic,pins = "GPIOY_12";
			amlogic,clrmask = <0x1 0x10000>;
			amlogic,setmask = <0x1 0x200>;
		};

		audio_suspend_pin {
			phandle = <0x58>;
			linux,phandle = <0x58>;
			amlogic,pullup = <0x0>;
			amlogic,pullupen = <0x1>;
			amlogic,pins = "GPIOAO_8", "GPIOAO_9", "GPIOAO_10", "GPIOAO_11";
			amlogic,clrmask = <0x10 0x78000000>;
		};

		audio_pin {
			phandle = <0x57>;
			linux,phandle = <0x57>;
			amlogic,pins = "GPIOAO_8", "GPIOAO_9", "GPIOAO_10", "GPIOAO_11";
			amlogic,clrmask = <0x10 0x40000>;
			amlogic,setmask = <0x10 0x78000000>;
		};

		dvb_s_ts0_pins {
			amlogic,pins = "GPIOY_0", "GPIOY_1", "GPIOY_2", "GPIOY_3";
			amlogic,clrmask = <0x2 0xf0000 0x1 0x7>;
			amlogic,setmask = <0x3 0x17>;
		};

		dvb_p_ts0_pins {
			amlogic,pins = "GPIOY_0", "GPIOY_1", "GPIOY_2", "GPIOY_3", "GPIOY_4", "GPIOY_5", "GPIOY_6", "GPIOY_7", "GPIOY_8", "GPIOY_9", "GPIOY_10";
			amlogic,clrmask = <0x2 0xf0000 0x1 0x30ff>;
			amlogic,setmask = <0x3 0x37>;
		};

		d_i2c {
			phandle = <0x12>;
			linux,phandle = <0x12>;
			amlogic,pins = "GPIOX_16", "GPIOX_17";
			amlogic,clrmask = <0x2 0x3000000 0x3 0x1000>;
			amlogic,setmask = <0x4 0xc>;
		};

		c_i2c {
			phandle = <0x11>;
			linux,phandle = <0x11>;
			amlogic,pins = "GPIODV_28", "GPIODV_29";
			amlogic,clrmask = <0x3 0x700000>;
			amlogic,setmask = <0x7 0xc00000>;
		};

		b_i2c {
			phandle = <0x10>;
			linux,phandle = <0x10>;
			amlogic,pins = "GPIODV_26", "GPIODV_27";
			amlogic,clrmask = <0x0 0x600 0x2 0xc000000 0x5 0x700>;
			amlogic,setmask = <0x7 0x3000000>;
		};

		a_i2c {
			phandle = <0xf>;
			linux,phandle = <0xf>;
			amlogic,pins = "GPIODV_24", "GPIODV_25";
			amlogic,clrmask = <0x0 0x18c0 0x2 0x30000000 0x5 0x1800>;
			amlogic,setmask = <0x7 0xc000000>;
		};

		hdmitx_eecec {
			amlogic,pins = "GPIOAO_12";
			amlogic,clrmask = <0x10 0x28000 0x11 0x1>;
			amlogic,setmask = <0x10 0x4000>;
		};

		hdmitx_aocec {
			phandle = <0x52>;
			linux,phandle = <0x52>;
			amlogic,pins = "GPIOAO_12";
			amlogic,clrmask = <0x10 0x24000 0x11 0x1>;
			amlogic,setmask = <0x10 0x8000>;
		};

		hdmitx_ddc {
			phandle = <0x50>;
			linux,phandle = <0x50>;
			amlogic,pins = "GPIOH_1", "GPIOH_2";
			amlogic,setmask = <0x1 0x3000000>;
		};

		hdmitx_hpd {
			phandle = <0x4f>;
			linux,phandle = <0x4f>;
			amlogic,pins = "GPIOH_0";
			amlogic,setmask = <0x1 0x4000000>;
		};

		nand_cs {
			phandle = <0x32>;
			linux,phandle = <0x32>;
			amlogic,pins = "BOOT_8", "BOOT_9";
			amlogic,clrmask = <0x4 0x40000>;
			amlogic,setmask = <0x4 0xc000000>;
		};

		all_nand_pins {
			phandle = <0x31>;
			linux,phandle = <0x31>;
			amlogic,enable-output = <0x1>;
			amlogic,pins = "BOOT_0", "BOOT_1", "BOOT_2", "BOOT_3", "BOOT_4", "BOOT_5", "BOOT_6", "BOOT_7", "BOOT_8", "BOOT_9", "BOOT_10", "BOOT_11", "BOOT_12", "BOOT_13", "BOOT_14", "BOOT_15", "BOOT_16", "BOOT_17";
			amlogic,clrmask = <0x0 0x80000 0x4 0x800c0000 0x5 0xf>;
			amlogic,setmask = <0x4 0x7ff00000>;
		};

		conf_nand_pullup {
			phandle = <0x30>;
			linux,phandle = <0x30>;
			amlogic,pullupen = <0x1>;
			amlogic,pullup = <0x1>;
			amlogic,pins = "BOOT_8", "BOOT_10";
		};

		conf_nand_pulldown {
			phandle = <0x2f>;
			linux,phandle = <0x2f>;
			amlogic,pullupen = <0x1>;
			amlogic,pullup = <0x0>;
			amlogic,pins = "BOOT_0", "BOOT_1", "BOOT_2", "BOOT_3", "BOOT_4", "BOOT_5", "BOOT_6", "BOOT_7", "BOOT_15";
		};

		sdio_all_pins {
			phandle = <0x2e>;
			linux,phandle = <0x2e>;
			amlogic,pullupen = <0x1>;
			amlogic,pullup = <0x1>;
			amlogic,enable-output = <0x1>;
			amlogic,pins = "GPIOX_0", "GPIOX_1", "GPIOX_2", "GPIOX_3", "GPIOX_4", "GPIOX_5";
			amlogic,setmask = <0x8 0x3f>;
		};

		sdio_clk_cmd_pins {
			phandle = <0x2d>;
			linux,phandle = <0x2d>;
			amlogic,pullupen = <0x1>;
			amlogic,pullup = <0x1>;
			amlogic,enable-output = <0x1>;
			amlogic,pins = "GPIOX_4", "GPIOX_5";
			amlogic,setmask = <0x8 0x3>;
		};

		emmc_all_pins {
			phandle = <0x2c>;
			linux,phandle = <0x2c>;
			amlogic,pullupen = <0x1>;
			amlogic,pullup = <0x1>;
			amlogic,enable-output = <0x1>;
			amlogic,pins = "BOOT_0", "BOOT_1", "BOOT_2", "BOOT_3", "BOOT_4", "BOOT_5", "BOOT_6", "BOOT_7", "BOOT_8", "BOOT_10";
			amlogic,setmask = <0x4 0xc00c0000>;
		};

		emmc_clk_cmd_pins {
			phandle = <0x2b>;
			linux,phandle = <0x2b>;
			amlogic,pullupen = <0x1>;
			amlogic,pullup = <0x1>;
			amlogic,enable-output = <0x1>;
			amlogic,pins = "BOOT_8", "BOOT_10";
			amlogic,setmask = <0x4 0xc00c0000>;
		};

		sd_to_ao_jtag_pins {
			phandle = <0x2a>;
			linux,phandle = <0x2a>;
			amlogic,pullupen = <0x1>;
			amlogic,pullup = <0x1>;
			amlogic,enable-output = <0x1>;
			amlogic,pins = "GPIOAO_0", "GPIOAO_1";
			amlogic,clrmask = <0x8 0x600 0x2 0xcc00>;
			amlogic,setmask = <0x10 0x1800>;
		};

		ao_to_sd_jtag_pins {
			phandle = <0x29>;
			linux,phandle = <0x29>;
			amlogic,pullupen = <0x1>;
			amlogic,pullup = <0x1>;
			amlogic,enable-output = <0x1>;
			amlogic,pins = "CARD_4", "CARD_5";
			amlogic,clrmask = <0x2 0xcc00 0x10 0x1800>;
			amlogic,setmask = <0x8 0x600>;
		};

		ao_to_sd_uart_pins {
			phandle = <0x28>;
			linux,phandle = <0x28>;
			amlogic,pullupen = <0x1>;
			amlogic,pullup = <0x1>;
			amlogic,enable-output = <0x1>;
			amlogic,pins = "CARD_4", "CARD_5";
			amlogic,clrmask = <0x10 0x1800 0x2 0x3000>;
			amlogic,setmask = <0x8 0x600>;
		};

		sd_to_ao_uart_pins {
			phandle = <0x27>;
			linux,phandle = <0x27>;
			amlogic,pullupen = <0x1>;
			amlogic,pullup = <0x1>;
			amlogic,enable-output = <0x1>;
			amlogic,pins = "GPIOAO_0", "GPIOAO_1";
			amlogic,clrmask = <0x8 0x600>;
			amlogic,setmask = <0x10 0x1800>;
		};

		sd_1bit_uart_pins {
			phandle = <0x26>;
			linux,phandle = <0x26>;
			amlogic,pullupen = <0x1>;
			amlogic,pullup = <0x1>;
			amlogic,enable-output = <0x1>;
			amlogic,pins = "CARD_1", "CARD_2", "CARD_3";
			amlogic,setmask = <0x2 0x8c00 0x8 0x600>;
		};

		sd_clk_cmd_uart_pins {
			phandle = <0x25>;
			linux,phandle = <0x25>;
			amlogic,pullupen = <0x1>;
			amlogic,pullup = <0x1>;
			amlogic,enable-output = <0x1>;
			amlogic,pins = "CARD_2", "CARD_3";
			amlogic,setmask = <0x2 0xc00 0x8 0x600>;
		};

		sd_1bit_pins {
			phandle = <0x24>;
			linux,phandle = <0x24>;
			amlogic,pullupen = <0x1>;
			amlogic,pullup = <0x1>;
			amlogic,enable-output = <0x1>;
			amlogic,pins = "CARD_1", "CARD_2", "CARD_3";
			amlogic,setmask = <0x2 0x8c00 0x10 0x1800>;
		};

		sd_all_pins {
			phandle = <0x23>;
			linux,phandle = <0x23>;
			amlogic,pullupen = <0x1>;
			amlogic,pullup = <0x1>;
			amlogic,enable-output = <0x1>;
			amlogic,pins = "CARD_0", "CARD_1", "CARD_2", "CARD_3", "CARD_4", "CARD_5";
			amlogic,setmask = <0x2 0xfc00 0x10 0x1800>;
		};

		sd_clk_cmd_pins {
			phandle = <0x22>;
			linux,phandle = <0x22>;
			amlogic,pullupen = <0x1>;
			amlogic,pullup = <0x1>;
			amlogic,enable-output = <0x1>;
			amlogic,pins = "CARD_2", "CARD_3";
			amlogic,setmask = <0x2 0xc00 0x10 0x1800>;
		};

		wifi_32k_pins {
			phandle = <0x21>;
			linux,phandle = <0x21>;
			amlogic,pins = "GPIOX_19";
			amlogic,clrmask = <0x2 0x400000 0x3 0x8000>;
			amlogic,setmask = <0x2 0x40000000>;
		};

		c_uart {
			amlogic,pins = "GPIOY_13", "GPIOY_14";
			amlogic,setmask = <0x1 0xc0000>;
		};

		b_uart {
			amlogic,pins = "GPIODV_24", "GPIODV_25";
			amlogic,setmask = <0x2 0x30000000>;
		};

		a_uart {
			phandle = <0x53>;
			linux,phandle = <0x53>;
			amlogic,pins = "GPIOX_12", "GPIOX_13", "GPIOX_14", "GPIOX_15";
			amlogic,setmask = <0x4 0x3c00>;
		};

		ao_b_uart {
			amlogic,pins = "GPIOAO_4", "GPIOAO_5";
			amlogic,setmask = <0x10 0x1800000>;
		};

		ao_uart {
			amlogic,pins = "GPIOAO_0", "GPIOAO_1";
			amlogic,setmask = <0x10 0x1800>;
		};

		remote_pin {
			phandle = <0x19>;
			linux,phandle = <0x19>;
			amlogic,pins = "GPIOAO_7";
			amlogic,setmask = <0x10 0x1>;
		};

		eth_pins {
			phandle = <0x1d>;
			linux,phandle = <0x1d>;
			amlogic,pins = "GPIOZ_0", "GPIOZ_1", "GPIOZ_2", "GPIOZ_3", "GPIOZ_4", "GPIOZ_5", "GPIOZ_6", "GPIOZ_7", "GPIOZ_8", "GPIOZ_9", "GPIOZ_10", "GPIOZ_11", "GPIOZ_12", "GPIOZ_13", "GPIOZ_15";
			amlogic,clrmask = <0x6 0xc000 0x5 0x3c0000f0 0x4 0x300>;
			amlogic,setmask = <0x6 0x3fff>;
		};

		ao-bank@c1108030 {
			phandle = <0x6b>;
			linux,phandle = <0x6b>;
			#gpio-cells = <0x2>;
			gpio-controller;
			reg-names = "mux", "pull", "gpio";
			reg = <0x0 0xc8100014 0x0 0x8 0x0 0xc810002c 0x0 0x4 0x0 0xc8100024 0x0 0x8>;
		};

		banks@c11080b0 {
			phandle = <0x1a>;
			linux,phandle = <0x1a>;
			#gpio-cells = <0x2>;
			gpio-controller;
			reg-names = "mux", "pull", "pull-enable", "gpio";
			reg = <0x0 0xc88344b0 0x0 0x28 0x0 0xc88344e8 0x0 0x14 0x0 0xc8834520 0x0 0x14 0x0 0xc8834430 0x0 0x40>;
		};
	};

	cpu_info {
		cpuinfo_cmd = <0x82000044>;
		compatible = "amlogic, cpuinfo";
	};

	meson_clock {
		phandle = <0xb>;
		linux,phandle = <0xb>;
		sys_max = <0x5b8d8000>;
		#reset-cells = <0x1>;
		#clock-cells = <0x1>;
		reg = <0x0 0xc883c000 0x0 0x1000 0x0 0xc8100000 0x0 0x1000>;
		compatible = "amlogic, gxbb-clock";
	};

	amlogic-watchdog {
		clocks = <0xb 0x2>;
		reg = <0x0 0xc11098d0 0x0 0x10>;
		suspend_timeout = <0x6>;
		firmware_timeout = <0x6>;
		shutdown_timeout = <0xa>;
		reset_watchdog_time = <0x2>;
		reset_watchdog_method = <0x1>;
		default_timeout = <0xa>;
		status = "disable";
		compatible = "amlogic, gx-wdt";
	};

	cpufreq-meson {
		clock-names = "cpu_clk";
		clocks = <0xe 0x0>;
		status = "okay";
		compatible = "amlogic, cpufreq-scpi";
	};

	cpu_iomap {
		ranges;
		#size-cells = <0x2>;
		#address-cells = <0x2>;
		compatible = "amlogic, iomap";

		io_aobus_base {
			reg = <0x0 0xc8100000 0x0 0x100000>;
		};

		io_apb_base {
			reg = <0x0 0xd0000000 0x0 0x200000>;
		};

		io_cbus_base {
			reg = <0x0 0xc1100000 0x0 0x100000>;
		};
	};

	securitykey {
		storage_size_func = <0x82000027>;
		storage_block_func = <0x82000025>;
		storage_out_func = <0x82000024>;
		storage_in_func = <0x82000023>;
		storage_remove = <0x82000068>;
		storage_list = <0x82000067>;
		storage_status = <0x82000065>;
		storage_verify = <0x82000064>;
		storage_tell = <0x82000063>;
		storage_write = <0x82000062>;
		storage_read = <0x82000061>;
		storage_query = <0x82000060>;
		compatible = "aml, securitykey";
	};

	secmon {
		out_base_func = <0x82000021>;
		in_base_func = <0x82000020>;
		memory-region = <0xd>;
		compatible = "amlogic, secmon";
	};

	psci {
		migrate = <0xc4000005>;
		cpu_on = <0xc4000003>;
		cpu_off = <0x84000002>;
		cpu_suspend = <0xc4000001>;
		method = "smc";
		compatible = "arm,psci";
	};

	aml_restart {
		sys_poweroff = <0x84000008>;
		sys_reset = <0x84000009>;
		compatible = "aml, restart";
	};

	interrupt-controller@2c001000 {
		phandle = <0x1>;
		linux,phandle = <0x1>;
		interrupts = <0x1 0x9 0xf04>;
		reg = <0x0 0xc4301000 0x0 0x1000 0x0 0xc4302000 0x0 0x100>;
		interrupt-controller;
		#address-cells = <0x0>;
		#interrupt-cells = <0x3>;
		compatible = "arm,cortex-a15-gic", "arm,cortex-a9-gic";
	};

	mali@d00c0000 {
		dvfs_tbl = <0xc>;
		control_interval = <0xc8>;
		clock-names = "fclk_div3", "fclk_div4", "fclk_div5", "fclk_div7", "gp0_pll", "clk_mali", "clk_mali_0", "clk_mali_1";
		clocks = <0xb 0x8 0xb 0x9 0xb 0x11 0xb 0x12 0xb 0x1e 0xb 0x15 0xb 0x13 0xb 0x14>;
		tbl = <0x2 0x5 0x7 0x8 0x9 0xa>;
		sc_mpp = <0x3>;
		def_clock = <0x3>;
		num_of_pp = <0x3>;
		pmu_switch_delay = <0xffff>;
		pmu_domain_config = <0x1 0x2 0x4 0x4 0x0 0x0 0x0 0x0 0x0 0x1 0x2 0x0>;
		interrupt-names = "IRQGP", "IRQGPMMU", "IRQPP", "IRQPMU", "IRQPP0", "IRQPPMMU0", "IRQPP1", "IRQPPMMU1", "IRQPP2", "IRQPPMMU2";
		interrupts = <0x0 0xa0 0x4 0x0 0xa1 0x4 0x0 0xa2 0x4 0x0 0xa3 0x4 0x0 0xa4 0x4 0x0 0xa5 0x4 0x0 0xa6 0x4 0x0 0xa7 0x4 0x0 0xa8 0x4 0x0 0xa9 0x4>;
		reg = <0x0 0xd00c0000 0x0 0x40000 0x0 0xc883c000 0x0 0x4 0x0 0xc8100000 0x0 0x4>;
		interrupt-parent = <0x1>;
		compatible = "arm,mali-450";

		clk800_cfg {
			phandle = <0xa>;
			linux,phandle = <0xa>;
			threshold = <0xe6 0xff>;
			keep_count = <0x5>;
			voltage = <0x47e>;
			clkp_freq = <0x2f34f600>;
			clk_parent = "gp0_pll";
			clk_freq = <0x2f34f600>;
		};

		clk666_cfg {
			phandle = <0x9>;
			linux,phandle = <0x9>;
			threshold = <0xd2 0xec>;
			keep_count = <0x5>;
			voltage = <0x47e>;
			clkp_freq = <0x27b25a80>;
			clk_parent = "fclk_div3";
			clk_freq = <0x27b25a80>;
		};

		clk500_cfg {
			phandle = <0x8>;
			linux,phandle = <0x8>;
			threshold = <0xb4 0xdc>;
			keep_count = <0x5>;
			voltage = <0x47e>;
			clkp_freq = <0x1dcd6500>;
			clk_parent = "fclk_div4";
			clk_freq = <0x1dcd6500>;
		};

		clk400_cfg {
			phandle = <0x7>;
			linux,phandle = <0x7>;
			threshold = <0x98 0xcf>;
			keep_count = <0x5>;
			voltage = <0x47e>;
			clkp_freq = <0x17d78400>;
			clk_parent = "fclk_div5";
			clk_freq = <0x17d78400>;
		};

		clk285_cfg {
			phandle = <0x5>;
			linux,phandle = <0x5>;
			threshold = <0x64 0xbe>;
			keep_count = <0x5>;
			voltage = <0x47e>;
			clkp_freq = <0x10fcc140>;
			clk_parent = "fclk_div7";
			clk_freq = <0x10fcc140>;
		};

		clk250_cfg {
			threshold = <0x50 0xaa>;
			keep_count = <0x5>;
			voltage = <0x47e>;
			clkp_freq = <0x1dcd6500>;
			clk_parent = "fclk_div4";
			clk_freq = <0xee6b280>;
		};

		clk125_cfg {
			phandle = <0x2>;
			linux,phandle = <0x2>;
			threshold = <0x1e 0x78>;
			keep_count = <0x5>;
			voltage = <0x47e>;
			clkp_freq = <0x1dcd6500>;
			clk_parent = "fclk_div4";
			clk_freq = <0x7735940>;
		};
	};

	pm {
		reg = <0x0 0xc81000a8 0x0 0x4 0x0 0xc810023c 0x0 0x4>;
		gxbaby-suspend;
		compatible = "amlogic, pm";
	};

	arm_pmu {
		interrupts = <0x0 0x89 0x4 0x0 0x8a 0x4 0x0 0x99 0x4 0x0 0x9a 0x4>;
		compatible = "arm,armv8-pmuv3";
	};

	timer {
		interrupts = <0x1 0xd 0xff01 0x1 0xe 0xff01 0x1 0xb 0xff01 0x1 0xa 0xff01>;
		compatible = "arm,armv8-timer";
	};

	cpus {
		#size-cells = <0x0>;
		#address-cells = <0x2>;

		cpu@3 {
			enable-method = "psci";
			reg = <0x0 0x3>;
			compatible = "arm,cortex-a53", "arm,armv8";
			device_type = "cpu";
		};

		cpu@2 {
			enable-method = "psci";
			reg = <0x0 0x2>;
			compatible = "arm,cortex-a53", "arm,armv8";
			device_type = "cpu";
		};

		cpu@1 {
			enable-method = "psci";
			reg = <0x0 0x1>;
			compatible = "arm,cortex-a53", "arm,armv8";
			device_type = "cpu";
		};

		cpu@0 {
			enable-method = "psci";
			reg = <0x0 0x0>;
			compatible = "arm,cortex-a53", "arm,armv8";
			device_type = "cpu";
		};
	};

	chosen {
		bootargs = "root=LABEL=ROOTFS rootflags=data=writeback rw console=ttyS0,115200n8 console=tty0 no_console_suspend consoleblank=0 fsck.fix=yes fsck.repair=yes net.ifnames=0 mac=${mac} ";
		linux,initrd-start = <0x0 0x33a32000>;
		linux,initrd-end = <0x0 0x33eb703b>;
	};
};
